# LPC18xx register map
File version: 18
Registers are 32-bit, read-write, reset 0x0 unless marked. A register's access mark holds for its fields unless they carry their own. Offsets are from the block's base; [hi:lo] are bit positions; {n}, {i} and the like mark numbered series.

## C_CAN1 — Product name title=UM10430 Chapter title=LPC18xx C_CAN Modification date=1/18/2011 Major revision=0 Minor revision=7
Base 0x400A4000
Same registers: C_CAN0 0x400E2000
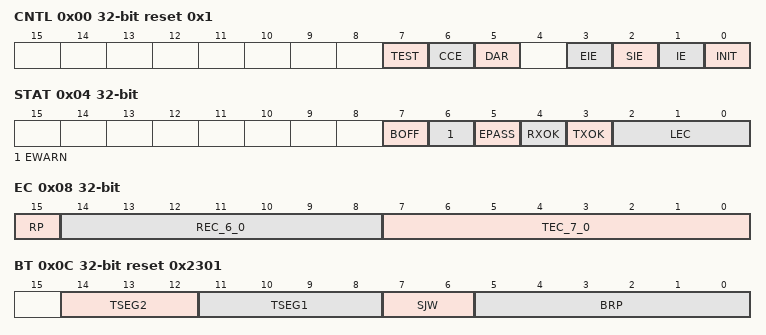
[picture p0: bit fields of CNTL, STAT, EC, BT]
0x00 CNTL reset 0x1 — CAN control
  [7] TEST — Test mode enable
    1=TEST_MODE_; 0=NORMAL_OPERATION_
  [6] CCE — Configuration change enable
    1=THE_CPU_HAS_WRITE_AC (The CPU has write access to the CANBT register while the INIT bit is one.); 0=THE_CPU_HAS_NO_WRITE (The CPU has no write access to the bit timing register.)
  [5] DAR — Disable automatic retransmission
    1=DISABLED (Automatic retransmission disabled.); 0=ENABLED (Automatic retransmission of disturbed messages enabled.)
  [3] EIE — Error interrupt enable
    1=ENABLE_ERROR_INTERRU (Enable error interrupt. A change in the bits BOFF or EWARN in the CANSTAT registers will generate an interrupt.); 0=DISABLE_ERROR_INTERR (Disable error interrupt. No error status interrupt will be generated.)
  [2] SIE — Status change interrupt enable
    1=ENABLE_STATUS_CHANGE (Enable status change interrupts. A status change interrupt will be generated when a message transfer is successfully completed or a CAN bus error is detected.); 0=DISABLE_STATUS_CHANG (Disable status change interrupts. No status change interrupt will be generated.)
  [1] IE — Module interrupt enable
    1=ENABLE_CAN_INTERRUPT (Enable CAN interrupts. The interrupt line is set to LOW and remains LOW until all pending interrupts are cleared.); 0=DISABLE_CAN_INTERRUP (Disable CAN interrupts. The interrupt line is always HIGH.)
  [0] INIT — Initialization
    1=INITIALIZATION_IS_ST (Initialization is started. On reset, software needs to initialize the CAN controller.); 0=NORMAL_OPERATION_
0x04 STAT — Status register
  [7] BOFF — Busoff status
    1=BUSOFF (The CAN controller is in busoff state.); 0=NOBUSOFF (The CAN module is not in busoff.)
  [6] EWARN — Warning status
    1=AT_LEAST_ONE_OF_THE_ (At least one of the error counters in the EML has reached the error warning limit of 96.); 0=BOTH_ERROR_COUNTERS_ (Both error counters are below the error warning limit of 96.)
  [5] EPASS — Error passive
    1=PASSIVE (The CAN controller is in the error passive state as defined in the CAN 2.0 specification.); 0=ACTIVE (The CAN controller is in the error active state.)
  [4] RXOK — Received a message successfully This bit is reset by the CPU. It is never reset by the CAN controller.
    1=MSGTRANSFER (Since this bit was last set to zero by the CPU, a message has been successfully received independent of the result of acceptance filtering.); 0=NOMSGTRANSFER (Since this bit was last reset by the CPU, no message has been successfully transmitted.)
  [3] TXOK — Transmitted a message successfully This bit is reset by the CPU. It is never reset by the CAN controller.
    1=MSGTRANSFER (Since this bit was last reset by the CPU, a message has been successfully transmitted (error free and acknowledged by at least one other node).); 0=NOMSGTRANSFER (Since this bit was reset by the CPU, no message has been successfully transmitted.)
  [2:0] LEC — Last error code Type of the last error to occur on the CAN bus.The LEC field holds a code which indicates the type of the last error to occur on the CAN bus. This field will be cleared to 0 when a message has been transferred (reception or transmission) without error. The unused code 111 may be written by the CPU to check for updates.
    0=NO_ERROR_; 1=STUFF_ERROR_MORE_TH (Stuff error: More than 5 equal bits in a sequence have occurred in a part of a received message where this is not allowed.); 2=FORM_ERROR_A_FIXED_ (Form error: A fixed format part of a received frame has the wrong format.); 3=ACKERROR_THE_MESSAG (AckError: The message this CAN core transmitted was not acknowledged.); 4=BIT1ERROR_DURING_TH (Bit1Error: During the transmission of a message (with the exception of the arbitration field), the device wanted to send a HIGH/recessive level (bit of logical value 1), but the monitored bus value was LOW/dominant.); 5=BIT0ERROR_DURING_TH (Bit0Error: During the transmission of a message (or acknowledge bit, or active error flag, or overload flag), the device wanted to send a LOW/dominant level (data or identifier bit logical value 0), but the monitored Bus value was HIGH/recessive. During busoff recovery this status is set each time a sequence of 11 HIGH/recessive bits has been monitored. This enables the CPU to monitor the proceeding of the busoff recovery sequence (indicating the bus is not stuck at LOW/dominant or continuously disturbed).); 6=CRCERROR_THE_CRC_CH (CRCError: The CRC checksum was incorrect in the message received.); 7=UNUSED_NO_CAN_BUS_E (Unused: No CAN bus event was detected (written by the CPU).)
0x08 EC ro — Error counter
  [15] RP — Receive error passive
    1=PASSIVE (The receive counter has reached the error passive level as defined in the CAN2.0 specification.); 0=BELOWPASSIVE (The receive counter is below the error passive level.)
  [14:8] REC_6_0 — Receive error counter Current value of the receive error counter (maximum value 255).
  [7:0] TEC_7_0 — Transmit error counter Current value of the transmit error counter (maximum value 127)
0x0C BT reset 0x2301 — Bit timing register
  [14:12] TSEG2 — Time segment before the sample point Valid values are 1 to 15[1].
  [11:8] TSEG1 — Time segment after the sample point Valid values are 0 to 7[1].
  [7:6] SJW — (Re)synchronization jump width Valid programmed values are 0 to 3[1].
  [5:0] BRP — Baud rate prescaler The value by which the oscillator frequency is divided for generating the bit time quanta. The bit time is built up from a multiple of this quanta. Valid values for the Baud Rate Prescaler are 0 to 63[1]. Valid programmed values are 0x01 - 0x3F[1].
0x10 INT ro — Interrupt register
  [15:0] INTID15_0 — 0x0000= No interrupt is pending 0x0001 to 0x0020 = Number of message object which caused the interrupt. 0x0021 to 0x7FFF = Unused 0x8000 = Status interrupt 0x8001 to 0xFFFF = Unused
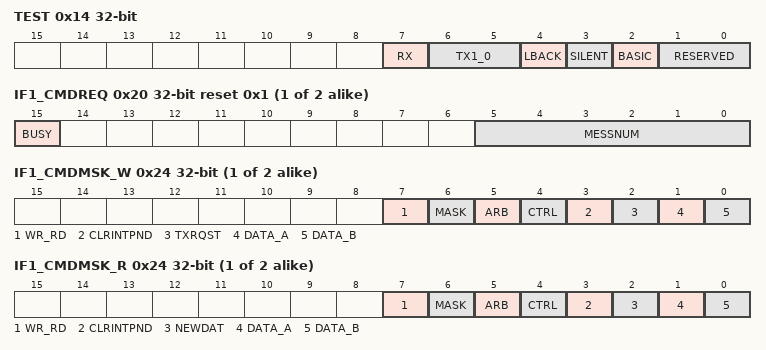
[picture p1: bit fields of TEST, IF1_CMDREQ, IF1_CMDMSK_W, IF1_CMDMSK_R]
0x14 TEST reset not defined
  [7] RX — Monitors the actual value of the RD Pin
    1=THE_CAN_BUS_IS_RECES (The CAN bus is recessive (RD = 1).); 0=THE_CAN_BUS_IS_DOMIN (The CAN bus is dominant (RD = 0).)
  [6:5] TX1_0 — Control of TD pins
    0=LEVEL_AT_THE_TD_PIN_ (Level at the TD pin is controlled by the CAN controller. This is the value at reset.); 1=THE_SAMPLE_POINT_CAN (The sample point can be monitored at the TD pin.); 2=TD_PIN_IS_DRIVEN_LOW (TD pin is driven LOW/dominant.); 3=TD_PIN_IS_DRIVEN_HIG (TD pin is driven HIGH/recessive.)
  [4] LBACK — Loop back mode
    1=ENABLED (Loop back mode is enabled.); 0=DISABLED (Loop back mode is disabled.)
  [3] SILENT — Silent mode
    1=SILENT (The module is in silent mode.); 0=NORMAL_OPERATION_
  [2] BASIC — Basic mode
    1=IF1_TX_if2_rx (IF1 registers used as TX buffer, IF2 registers used as RX buffer.); 0=BASIC_MODE_DISABLED_
  [1:0] RESERVED
0x18 BRPE — Baud rate prescaler extension register
  [3:0] BRPE — Baud rate prescaler extension By programming BRPE the Baud Rate Prescaler can be extended to values up to 1023. Hardware interprets the value as the value of BRPE (MSBs) and BRP (LSBs) plus one. Allowed values are 0x00 to 0x0F
0x20 IF{i}_CMDREQ (i=1..2; step 0x60) reset 0x1 — Message interface command request
  [15] BUSY — BUSY flag. Set to one by hardware when writing to this Command request register. Set to zero by hardware when read/write action to this Command request register has finished.
  [5:0] MESSNUM — Message number 0x01 to 0x20 = Valid message numbers The message object in the message RAM is selected for data transfer. 0x00 = Not a valid message number. This value is interpreted as 0x20.[1] 0x21 to 0x3F = Not a valid message number. This value is interpreted as 0x01 - 0x1F.[1]
0x24 IF{i}_CMDMSK_W (i=1..2; step 0x60) — Message interface command mask (write direction)
  [7] WR_RD — Write transfer Transfer data from the selected message buffer registers to the message object addressed by the command request register CANIFn_CMDREQ.
  [6] MASK — Access mask bits
    1=TRANSFER_IDENTIFIER_ (Transfer Identifier MASK + MDIR + MXTD to message object.); 0=MASK_BITS_UNCHANGED_
  [5] ARB — Access arbitration bits
    1=TRANSFER_IDENTIFIER, (Transfer Identifier, DIR, XTD, and MSGVAL bits to message object.); 0=ARBITRATION_BITS_UNC (Arbitration bits unchanged.)
  [4] CTRL — Access control bits
    1=TRANSFER_CONTROL_BIT (Transfer control bits to message object); 0=CONTROL_BITS_UNCHANG (Control bits unchanged.)
  [3] CLRINTPND — This bit is ignored in the write direction.
  [2] TXRQST — Access transmission request bit
    1=REQUEST_A_TRANSMISSI (Request a transmission. Set the TXRQST bit IF1/2_MCTRL.); 0=NO_TRANSMISSION_REQU (No transmission request. TXRQSRT bit unchanged in IF1/2_MCTRL. If a transmission is requested by programming this bit, the TXRQST bit in the CANIFn_MCTRL register is ignored.)
  [1] DATA_A — Access data bytes 0-3
    1=TRANSFER_DATA_BYTES_ (Transfer data bytes 0-3 to message object.); 0=DATA_BYTES_0_3_UNCHA (data bytes 0-3 unchanged.)
  [0] DATA_B — Access data bytes 4-7
    1=TRANSFER_DATA_BYTES_ (Transfer data bytes 4-7 to message object.); 0=DATA_BYTES_4_7_UNCHA (data bytes 4-7 unchanged.)
0x24 IF{i}_CMDMSK_R (i=1..2; step 0x60) (alternate view of IF{i}_CMDMSK_W) — Message interface command mask (read direction)
  [7] WR_RD — Read transfer Transfer data from the message object addressed by the command request register to the selected message buffer registers CANIFn_CMDREQ.
  [6] MASK — Access mask bits
    1=TRANSFER_IDENTIFIER_ (Transfer Identifier MASK + MDIR + MXTD to IFx message buffer register.); 0=MASK_BITS_UNCHANGED_
  [5] ARB — Access arbitration bits
    1=TRANSFER_IDENTIFIER, (Transfer Identifier, DIR, XTD, and MSGVAL bits to IFx message buffer register.); 0=ARBITRATION_BITS_UNC (Arbitration bits unchanged.)
  [4] CTRL — Access control bits
    1=TRANSFER_CONTROL_BIT (Transfer control bits to IFx message buffer.); 0=CONTROL_BITS_UNCHANG (Control bits unchanged.)
  [3] CLRINTPND — Clear interrupt pending bit.
    1=CLEAR_INTPND_BIT_IN_ (Clear INTPND bit in the message object.); 0=INTPND_BIT_REMAINS_U (INTPND bit remains unchanged.)
  [2] NEWDAT — Access new data bit
    1=CLEAR_NEWDAT_BIT_IN_ (Clear NEWDAT bit in the message object.); 0=NEWDAT_BIT_REMAINS_U (NEWDAT bit remains unchanged. A read access to a message object can be combined with the reset of the control bits INTPND and NEWDAT in IF1/2_MCTRL. The values of these bits transferred to the IFx Message Control Register always reflect the status before resetting these bits.)
  [1] DATA_A — Access data bytes 0-3
    1=TRANSFER_DATA_BYTES_ (Transfer data bytes 0-3 to IFx message buffer.); 0=DATA_BYTES_0_3_UNCHA (data bytes 0-3 unchanged.)
  [0] DATA_B — Access data bytes 4-7
    1=TRANSFER_DATA_BYTES_ (Transfer data bytes 4-7 to IFx message buffer register.); 0=DATA_BYTES_4_7_UNCHA (data bytes 4-7 unchanged.)
0x28 IF{i}_MSK1 (i=1..2; step 0x60) reset 0xFFFF — Message interface mask 1
  [15:0] MSK15_0 — Identifier mask 0 = The corresponding bit in the identifier of the message can not inhibit the match in the acceptance filtering. 1 = The corresponding identifier bit is used for acceptance filtering.
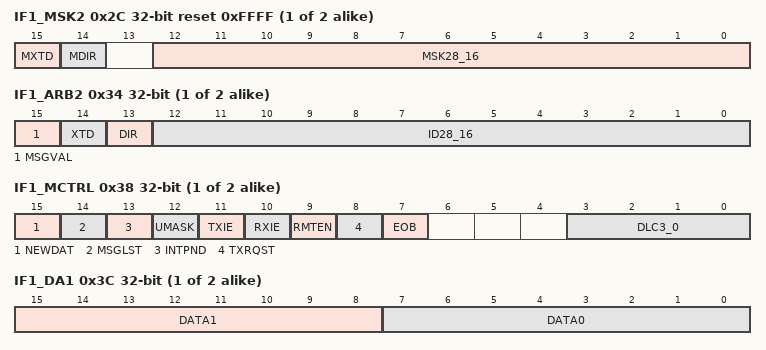
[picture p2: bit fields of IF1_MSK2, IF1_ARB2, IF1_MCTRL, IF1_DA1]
0x2C IF{i}_MSK2 (i=1..2; step 0x60) reset 0xFFFF — Message interface 1 mask 2
  [15] MXTD — Mask extend identifier
    1=THE_EXTENDED_IDENTIF (The extended identifier bit (IDE) is used for acceptance filtering.); 0=THE_EXTENDED_IDENTIF (The extended identifier bit (IDE) has no effect on acceptance filtering.)
  [14] MDIR — Mask message direction
    1=THE_MESSAGE_DIRECTIO (The message direction bit (DIR) is used for acceptance filtering.); 0=THE_MESSAGE_DIRECTIO (The message direction bit (DIR) has no effect on acceptance filtering.)
  [12:0] MSK28_16 — Identifier mask 0 = The corresponding bit in the identifier of the message can not inhibit the match in the acceptance filtering. 1 = The corresponding identifier bit is used for acceptance filtering.
0x30 IF{i}_ARB1 (i=1..2; step 0x60) — Message interface 1 arbitration 1
  [15:0] ID15_0 — Message identifier 29-bit identifier (extended frame) 11-bit identifier (standard frame)
0x34 IF{i}_ARB2 (i=1..2; step 0x60) — Message interface 1 arbitration 2
  [15] MSGVAL — Message valid The CPU must reset the MSGVAL bit of all unused Messages Objects during the initialization before it resets bit INIT in the CAN Control Register. This bit must also be reset before the identifier ID28:0, the control bits XTD, DIR, or the Data Length Code DLC3:0 are modified, or if the Messages Object is no longer required.
    1=THE_MESSAGE_OBJECT_I (The message object is configured and should be considered by the message handler.); 0=THE_MESSAGE_OBJECT_I (The message object is ignored by the message handler.)
  [14] XTD — Extend identifier
    1=THE_29_BIT_EXTENDED_ (The 29-bit extended identifier will be used for this message object.); 0=THE_11_BIT_STANDARD_ (The 11-bit standard identifier will be used for this message object.)
  [13] DIR — Message direction
    1=DIRECTION_EQ_TRANSMIT (Direction = transmit. On TXRQST, the respective Message Object is transmitted as a Data Frame. On reception of a Remote Frame with matching identifier, the TXRQST bit of this Message Object is set (if RMTEN = one).); 0=DIRECTION_EQ_RECEIVE_ (Direction = receive. On TXRQST, a Remote Frame with the identifier of this Message Object is transmitted. On reception of a Data Frame with matching identifier, that message is stored in this Message Object.)
  [12:0] ID28_16 — Message identifier 29-bit identifier (extended frame) 11-bit identifier (standard frame)
0x38 IF{i}_MCTRL (i=1..2; step 0x60) — Message interface 1 message control
  [15] NEWDAT — New data
    1=THE_MESSAGE_HANDLER_ (The message handler or the CPU has written new data into the data portion of this message object.); 0=NO_NEW_DATA_HAS_BEEN (No new data has been written into the data portion of this message object by the message handler since this flag was cleared last by the CPU.)
  [14] MSGLST — Message lost (only valid for message objects in the direction receive).
    1=THE_MESSAGE_HANDLER_ (The Message Handler stored a new message into this object when NEWDAT was still set, the CPU has lost a message.); 0=NO_MESSAGE_LOST_SINC (No message lost since this bit was reset last by the CPU.)
  [13] INTPND — Interrupt pending
    1=INTSOURCE (This message object is the source of an interrupt. The Interrupt Identifier in the Interrupt Register will point to this message object if there is no other interrupt source with higher priority.); 0=NOINTSOURCE (This message object is not the source of an interrupt.)
  [12] UMASK — Use acceptance mask If UMASK is set to 1, the message object's mask bits have to be programmed during initialization of the message object before MAGVAL is set to 1.
    1=USE_MASK_(MSK[280], (Use mask (MSK[28:0], MXTD, and MDIR) for acceptance filtering.); 0=MASK_IGNORED_
  [11] TXIE — Transmit interrupt enable
    1=INTPNDSET (INTPND will be set after a successful reception of a frame.); 0=UNCHANGED (The INTPND bit will be left unchanged after a successful reception of a frame.)
  [10] RXIE — Receive interrupt enable
    1=INTPNDSET (INTPND will be set after successful reception of a frame.); 0=UNCHANGED (INTPND will be left unchanged after successful reception of a frame.)
  [9] RMTEN — Remote enable
    1=TXRQSTSET (At the reception of a remote frame, TXRQST is set.); 0=UNCHANGED (At the reception of a remote frame, TXRQST is left unchanged.)
  [8] TXRQST — Transmit request
    1=REQUEST (The transmission of this message object is requested and is not yet done); 0=WAIT (This message object is not waiting for transmission.)
  [7] EOB — End of buffer
    1=SINGLE_MESSAGE_OBJEC (Single message object or last message object of a FIFO buffer.); 0=MESSAGE_OBJECT_BELON (Message object belongs to a FIFO buffer and is not the last message object of that FIFO buffer.)
  [3:0] DLC3_0 — Data length code The Data Length Code of a Message Object must be defined the same as in all the corresponding objects with the same identifier at other nodes. When the Message Handler stores a data frame, it will write the DLC to the value given by the received message. 0000 to 1000 = Data frame has 0 - 8 data bytes. 1001 to 1111 = Data frame has 8 data bytes.
0x3C IF{i}_DA1 (i=1..2; step 0x60) — Message interface data A1
  [15:8] DATA1 — Data byte 1
  [7:0] DATA0 — Data byte 0
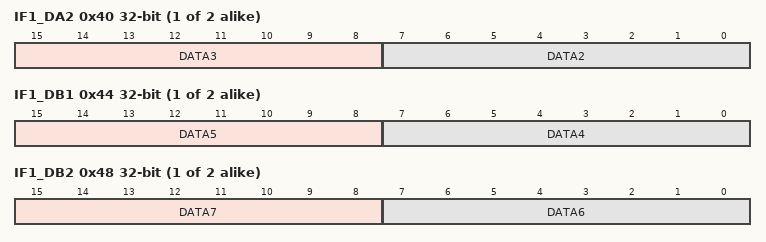
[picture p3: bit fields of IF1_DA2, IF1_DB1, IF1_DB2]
0x40 IF{i}_DA2 (i=1..2; step 0x60) — Message interface 1 data A2
  [15:8] DATA3 — Data byte 3
  [7:0] DATA2 — Data byte 2
0x44 IF{i}_DB1 (i=1..2; step 0x60) — Message interface 1 data B1
  [15:8] DATA5 — Data byte 5
  [7:0] DATA4 — Data byte 4
0x48 IF{i}_DB2 (i=1..2; step 0x60) — Message interface 1 data B2
  [15:8] DATA7 — Data byte 7
  [7:0] DATA6 — Data byte 6
0x100 TXREQ1 ro — Transmission request 1
  [15:0] TXRQST16_1 — Transmission request bit of message objects 16 to 1. 0 = This message object is not waiting for transmission. 1 = The transmission of this message object is requested and not yet done.
0x104 TXREQ2 ro — Transmission request 2
  [15:0] TXRQST32_17 — Transmission request bit of message objects 32 to 17. 0 = This message object is not waiting for transmission. 1 = The transmission of this message object is requested and not yet done.
0x120 ND1 ro — New data 1
  [15:0] NEWDAT16_1 — New data bits of message objects 16 to 1. 0 = No new data has been written into the data portion of this Message Object by the Message Handler since last time this flag was cleared by the CPU. 1 = The Message Handler or the CPU has written new data into the data portion of this Message Object.
0x124 ND2 ro — New data 2
  [15:0] NEWDAT32_17 — New data bits of message objects 32 to 17. 0 = No new data has been written into the data portion of this Message Object by the Message Handler since last time this flag was cleared by the CPU. 1 = The Message Handler or the CPU has written new data into the data portion of this Message Object.
0x140 IR1 ro — Interrupt pending 1
  [15:0] INTPND16_1 — Interrupt pending bits of message objects 16 to 1. 0 = This message object is ignored by the message handler. 1 = This message object is the source of an interrupt.
0x144 IR2 ro — Interrupt pending 2
  [15:0] INTPND32_17 — Interrupt pending bits of message objects 32 to 17. 0 = This message object is ignored by the message handler. 1 = This message object is the source of an interrupt.
0x160 MSGV1 ro — Message valid 1
  [15:0] MSGVAL16_1 — Message valid bits of message objects 16 to 1. 0 = This message object is ignored by the message handler. 1 = This message object is configured and should be considered by the message handler.
0x164 MSGV2 ro — Message valid 2
  [15:0] MSGVAL32_17 — Message valid bits of message objects 32 to 17. 0 = This message object is ignored by the message handler. 1 = This message object is configured and should be considered by the message handler.
0x180 CLKDIV reset 0x1 — CAN clock divider register
  [3:0] CLKDIVVAL — Clock divider value CAN_CLK = PCLK/(2CLKDIVVAL -1+1) 0000: CAN_CLK = PCLK divided by 1. 0001: CAN_CLK = PCLK divided by 2. 0010: CAN_CLK = PCLK divided by 3. 0010: CAN_CLK = PCLK divided by 4. 0011: CAN_CLK = PCLK divided by 5. 0100: CAN_CLK = PCLK divided by 9. 0101: CAN_CLK = PCLK divided by 17. ... 1111: CAN_CLK = PCLK divided by 16385.
